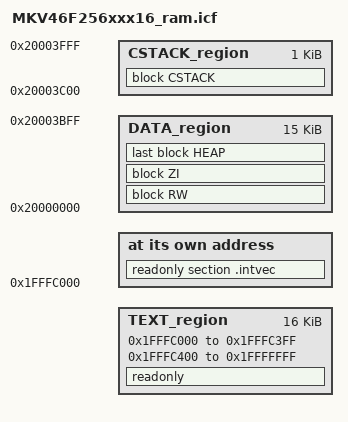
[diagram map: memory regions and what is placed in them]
/*
** ###################################################################
**     Processors:          MKV46F256VLH16
**                          MKV46F256VLL16
**
**     Compiler:            IAR ANSI C/C++ Compiler for ARM
**     Reference manual:    KV4XP100M168RM Rev 3.2, 09/2015
**     Version:             rev. 1.3, 2015-07-29
**     Build:               b190916
**
**     Abstract:
**         Linker file for the IAR ANSI C/C++ Compiler for ARM
**
**     Copyright 2016 Freescale Semiconductor, Inc.
**     Copyright 2016-2019 NXP
**     All rights reserved.
**
**     SPDX-License-Identifier: BSD-3-Clause
**
**     http:                 www.nxp.com
**     mail:                 support@nxp.com
**
** ###################################################################
*/

define symbol m_interrupts_start       = 0x1FFFC000;
define symbol m_interrupts_end         = 0x1FFFC3FF;

define symbol m_text_start             = 0x1FFFC400;
define symbol m_text_end               = 0x1FFFFFFF;

define symbol m_data_start             = 0x20000000;
define symbol m_data_end               = 0x20003FFF;

/* Sizes */
if (isdefinedsymbol(__stack_size__)) {
  define symbol __size_cstack__        = __stack_size__;
} else {
  define symbol __size_cstack__        = 0x0400;
}

if (isdefinedsymbol(__heap_size__)) {
  define symbol __size_heap__          = __heap_size__;
} else {
  define symbol __size_heap__          = 0x0400;
}


define memory mem with size = 4G;
define region TEXT_region = mem:[from m_interrupts_start to m_interrupts_end]
                          | mem:[from m_text_start to m_text_end];
define region DATA_region = mem:[from m_data_start to m_data_end-__size_cstack__];
define region CSTACK_region = mem:[from m_data_end-__size_cstack__+1 to m_data_end];

define block CSTACK    with alignment = 8, size = __size_cstack__   { };
define block HEAP      with alignment = 8, size = __size_heap__     { };
define block RW        { readwrite };
define block ZI        { zi };

initialize by copy { readwrite, section .textrw };
do not initialize  { section .noinit };

place at address mem: m_interrupts_start    { readonly section .intvec };
place in TEXT_region                        { readonly };
place in DATA_region                        { block RW };
place in DATA_region                        { block ZI };
place in DATA_region                        { last block HEAP };
place in CSTACK_region                      { block CSTACK };

